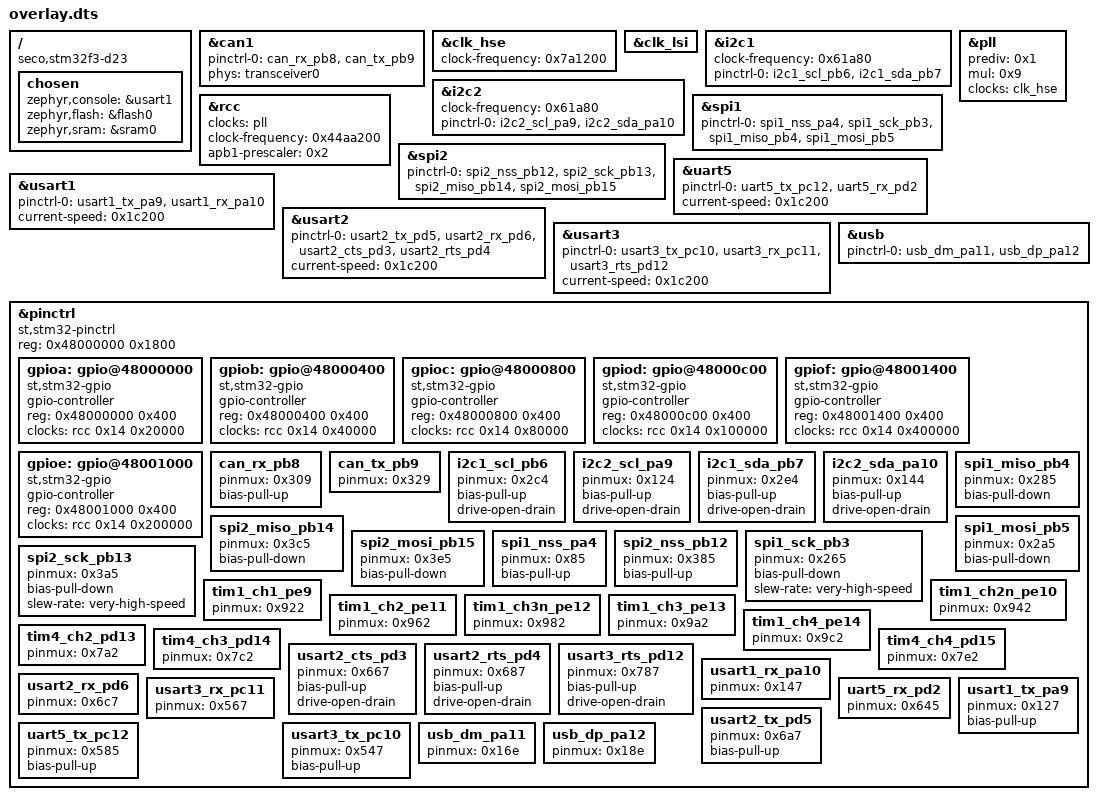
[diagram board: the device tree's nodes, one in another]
/ {
	compatible = "seco,stm32f3-d23";
	chosen {
		zephyr,console = &usart1;
		zephyr,flash = &flash0;
		zephyr,sram = &sram0;
	};
};
&can1{
	status = "okay";
	pinctrl-0 = < &can_rx_pb8 &can_tx_pb9 >;
	pinctrl-names = "default";
	phys = < &transceiver0 >;
};
&clk_hse{
	status = "okay";
	clock-frequency = < 0x7a1200 >;
};
&clk_lsi{
	status = "okay";
};
&i2c1{
	clock-frequency = < 0x61a80 >;
	status = "okay";
	pinctrl-0 = < &i2c1_scl_pb6 &i2c1_sda_pb7 >;
	pinctrl-names = "default";
};
&i2c2{
	clock-frequency = < 0x61a80 >;
	pinctrl-0 = < &i2c2_scl_pa9 &i2c2_sda_pa10 >;
	pinctrl-names = "default";
};
&pll{
	status = "okay";
	prediv = < 0x1 >;
	mul = < 0x9 >;
	clocks = < &clk_hse >;
};
&rcc{
	clocks = < &pll >;
	clock-frequency = < 0x44aa200 >;
	apb1-prescaler = < 0x2 >;
	status = "okay";
};
&spi1{
	status = "okay";
	pinctrl-0 = < &spi1_nss_pa4 &spi1_sck_pb3 &spi1_miso_pb4 &spi1_mosi_pb5 >;
	pinctrl-names = "default";
};
&spi2{
	status = "okay";
	pinctrl-0 = < &spi2_nss_pb12 &spi2_sck_pb13 &spi2_miso_pb14 &spi2_mosi_pb15 >;
	pinctrl-names = "default";
};
&uart5{
	pinctrl-0 = < &uart5_tx_pc12 &uart5_rx_pd2 >;
	pinctrl-names = "default";
	current-speed = < 0x1c200 >;
};
&usart1{
	status = "okay";
	pinctrl-0 = < &usart1_tx_pa9 &usart1_rx_pa10 >;
	pinctrl-names = "default";
	current-speed = < 0x1c200 >;
};
&usart2{
	pinctrl-0 = < &usart2_tx_pd5 &usart2_rx_pd6 &usart2_cts_pd3 &usart2_rts_pd4 >;
	pinctrl-names = "default";
	current-speed = < 0x1c200 >;
};
&usart3{
	pinctrl-0 = < &usart3_tx_pc10 &usart3_rx_pc11 &usart3_rts_pd12 >;
	pinctrl-names = "default";
	current-speed = < 0x1c200 >;
};
&usb{
	status = "okay";
	pinctrl-0 = < &usb_dm_pa11 &usb_dp_pa12 >;
	pinctrl-names = "default";
};
&pinctrl{
	compatible = "st,stm32-pinctrl";
	#address-cells = < 0x1 >;
	#size-cells = < 0x1 >;
	reg = < 0x48000000 0x1800 >;
	gpioa: gpio@48000000 {
		compatible = "st,stm32-gpio";
		gpio-controller;
		#gpio-cells = < 0x2 >;
		reg = < 0x48000000 0x400 >;
		clocks = < &rcc 0x14 0x20000 >;
	};
	gpiob: gpio@48000400 {
		compatible = "st,stm32-gpio";
		gpio-controller;
		#gpio-cells = < 0x2 >;
		reg = < 0x48000400 0x400 >;
		clocks = < &rcc 0x14 0x40000 >;
	};
	gpioc: gpio@48000800 {
		compatible = "st,stm32-gpio";
		gpio-controller;
		#gpio-cells = < 0x2 >;
		reg = < 0x48000800 0x400 >;
		clocks = < &rcc 0x14 0x80000 >;
	};
	gpiod: gpio@48000c00 {
		compatible = "st,stm32-gpio";
		gpio-controller;
		#gpio-cells = < 0x2 >;
		reg = < 0x48000c00 0x400 >;
		clocks = < &rcc 0x14 0x100000 >;
	};
	gpiof: gpio@48001400 {
		compatible = "st,stm32-gpio";
		gpio-controller;
		#gpio-cells = < 0x2 >;
		reg = < 0x48001400 0x400 >;
		clocks = < &rcc 0x14 0x400000 >;
	};
	gpioe: gpio@48001000 {
		compatible = "st,stm32-gpio";
		gpio-controller;
		#gpio-cells = < 0x2 >;
		reg = < 0x48001000 0x400 >;
		clocks = < &rcc 0x14 0x200000 >;
	};
	can_rx_pb8: can_rx_pb8 {
		pinmux = < 0x309 >;
		bias-pull-up;
	};
	can_tx_pb9: can_tx_pb9 {
		pinmux = < 0x329 >;
	};
	i2c1_scl_pb6: i2c1_scl_pb6 {
		pinmux = < 0x2c4 >;
		bias-pull-up;
		drive-open-drain;
	};
	i2c2_scl_pa9: i2c2_scl_pa9 {
		pinmux = < 0x124 >;
		bias-pull-up;
		drive-open-drain;
	};
	i2c1_sda_pb7: i2c1_sda_pb7 {
		pinmux = < 0x2e4 >;
		bias-pull-up;
		drive-open-drain;
	};
	i2c2_sda_pa10: i2c2_sda_pa10 {
		pinmux = < 0x144 >;
		bias-pull-up;
		drive-open-drain;
	};
	spi1_miso_pb4: spi1_miso_pb4 {
		pinmux = < 0x285 >;
		bias-pull-down;
	};
	spi2_miso_pb14: spi2_miso_pb14 {
		pinmux = < 0x3c5 >;
		bias-pull-down;
	};
	spi1_mosi_pb5: spi1_mosi_pb5 {
		pinmux = < 0x2a5 >;
		bias-pull-down;
	};
	spi2_mosi_pb15: spi2_mosi_pb15 {
		pinmux = < 0x3e5 >;
		bias-pull-down;
	};
	spi1_nss_pa4: spi1_nss_pa4 {
		pinmux = < 0x85 >;
		bias-pull-up;
	};
	spi2_nss_pb12: spi2_nss_pb12 {
		pinmux = < 0x385 >;
		bias-pull-up;
	};
	spi1_sck_pb3: spi1_sck_pb3 {
		pinmux = < 0x265 >;
		bias-pull-down;
		slew-rate = "very-high-speed";
	};
	spi2_sck_pb13: spi2_sck_pb13 {
		pinmux = < 0x3a5 >;
		bias-pull-down;
		slew-rate = "very-high-speed";
	};
	tim1_ch1_pe9: tim1_ch1_pe9 {
		pinmux = < 0x922 >;
	};
	tim1_ch2n_pe10: tim1_ch2n_pe10 {
		pinmux = < 0x942 >;
	};
	tim1_ch2_pe11: tim1_ch2_pe11 {
		pinmux = < 0x962 >;
	};
	tim1_ch3n_pe12: tim1_ch3n_pe12 {
		pinmux = < 0x982 >;
	};
	tim1_ch3_pe13: tim1_ch3_pe13 {
		pinmux = < 0x9a2 >;
	};
	tim1_ch4_pe14: tim1_ch4_pe14 {
		pinmux = < 0x9c2 >;
	};
	tim4_ch2_pd13: tim4_ch2_pd13 {
		pinmux = < 0x7a2 >;
	};
	tim4_ch3_pd14: tim4_ch3_pd14 {
		pinmux = < 0x7c2 >;
	};
	tim4_ch4_pd15: tim4_ch4_pd15 {
		pinmux = < 0x7e2 >;
	};
	usart2_cts_pd3: usart2_cts_pd3 {
		pinmux = < 0x667 >;
		bias-pull-up;
		drive-open-drain;
	};
	usart2_rts_pd4: usart2_rts_pd4 {
		pinmux = < 0x687 >;
		bias-pull-up;
		drive-open-drain;
	};
	usart3_rts_pd12: usart3_rts_pd12 {
		pinmux = < 0x787 >;
		bias-pull-up;
		drive-open-drain;
	};
	usart1_rx_pa10: usart1_rx_pa10 {
		pinmux = < 0x147 >;
	};
	usart2_rx_pd6: usart2_rx_pd6 {
		pinmux = < 0x6c7 >;
	};
	usart3_rx_pc11: usart3_rx_pc11 {
		pinmux = < 0x567 >;
	};
	uart5_rx_pd2: uart5_rx_pd2 {
		pinmux = < 0x645 >;
	};
	usart1_tx_pa9: usart1_tx_pa9 {
		pinmux = < 0x127 >;
		bias-pull-up;
	};
	usart2_tx_pd5: usart2_tx_pd5 {
		pinmux = < 0x6a7 >;
		bias-pull-up;
	};
	usart3_tx_pc10: usart3_tx_pc10 {
		pinmux = < 0x547 >;
		bias-pull-up;
	};
	uart5_tx_pc12: uart5_tx_pc12 {
		pinmux = < 0x585 >;
		bias-pull-up;
	};
	usb_dm_pa11: usb_dm_pa11 {
		pinmux = < 0x16e >;
	};
	usb_dp_pa12: usb_dp_pa12 {
		pinmux = < 0x18e >;
	};
};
